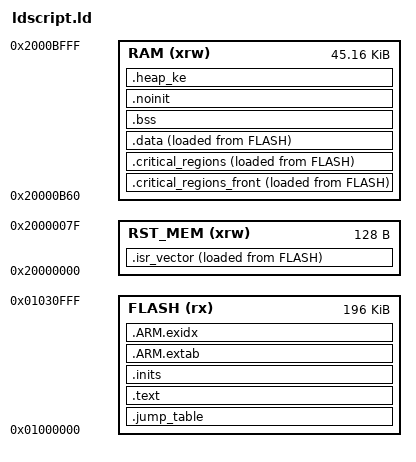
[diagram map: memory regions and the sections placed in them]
/*
 * Memory Spaces Definitions.
 *
 * Need modifying for a specific board. 
 *   FLASH.ORIGIN: starting address of flash
 *   FLASH.LENGTH: length of flash
 *   RAM.ORIGIN: starting address of RAM bank 0
 *   RAM.LENGTH: length of RAM bank 0
 *
 * The values below can be addressed in further linker scripts
 * using functions like 'ORIGIN(RAM)' or 'LENGTH(RAM)'.
 */

MEMORY
{
  FLASH (rx)    : ORIGIN = 0x01000000, LENGTH = 196K
  RST_MEM (xrw) : ORIGIN = 0x20000000, LENGTH = 0x80
  RAM (xrw)     : ORIGIN = 0x20000B60, LENGTH = 0xB4A0
}

/* 
 * The entry point is informative, for debuggers and simulators,
 * since the Cortex-M vector points to it anyway.
 */
ENTRY(app_main)


/* Sections Definitions */

SECTIONS
{
    .jump_table : ALIGN(4)
    {
        KEEP(*(jump_table_0))
        KEEP(*(jump_table_1))
        KEEP(*(jump_table_2))
        KEEP(*(jump_table_3))
        KEEP(*(jump_table_4))
        *(jump_table_0)
        *(jump_table_1)
        *(jump_table_2)
        *(jump_table_3)
        *(jump_table_4)
    } >FLASH
    
    /*
     * The program code is stored in the .text section, 
     * which goes to FLASH.
     */
    .text : ALIGN(4)
    {
        *(.text .text.*)            /* all remaining code */
 
        /* read-only data (constants) */
        *(.rodata .rodata.* .constdata .constdata.*)        

        KEEP(*(.eh_frame*))

        /*
         * Stub sections generated by the linker, to glue together 
         * ARM and Thumb code. .glue_7 is used for ARM code calling 
         * Thumb code, and .glue_7t is used for Thumb code calling 
         * ARM code. Apparently always generated by the linker, for some
         * architectures, so better leave them here.
         */
        *(.glue_7)
        *(.glue_7t)

    } >FLASH

    .inits : ALIGN(4)
    {
        /* 
         * Memory regions initialisation arrays.
         *
         * Thee are two kinds of arrays for each RAM region, one for 
         * data and one for bss. Each is iterrated at startup and the   
         * region initialisation is performed.
         * 
         * The data array includes:
         * - from (LOADADDR())
         * - region_begin (ADDR())
         * - region_end (ADDR()+SIZEOF())
         *
         * The bss array includes:
         * - region_begin (ADDR())
         * - region_end (ADDR()+SIZEOF())
         *
         * WARNING: It is mandatory that the regions are word aligned, 
         * since the initialisation code works only on words.
         */
         
        __vector_regions_array_start = .;
        LONG(LOADADDR(.isr_vector));
        LONG(ADDR(.isr_vector));
        LONG(ADDR(.isr_vector)+SIZEOF(.isr_vector));
        __vector_regions_array_end = .;
        
        __critical_regions_array_front_start = .;
        LONG(LOADADDR(.critical_regions_front));
        LONG(ADDR(.critical_regions_front));
        LONG(ADDR(.critical_regions_front)+SIZEOF(.critical_regions_front));
        __critical_regions_array_front_end = .;
        
        __critical_regions_array_start = .;
        LONG(LOADADDR(.critical_regions));
        LONG(ADDR(.critical_regions));
        LONG(ADDR(.critical_regions)+SIZEOF(.critical_regions));
        __critical_regions_array_end = .;
         
        __data_regions_array_start = .;
        LONG(LOADADDR(.data));
        LONG(ADDR(.data));
        LONG(ADDR(.data)+SIZEOF(.data));
        __data_regions_array_end = .;
        
        __bss_regions_array_start = .;
        LONG(ADDR(.bss));
        LONG(ADDR(.bss)+SIZEOF(.bss));
        __bss_regions_array_end = .;

        /* End of memory regions initialisation arrays. */
    
        /*
         * These are the old initialisation sections, intended to contain
         * naked code, with the prologue/epilogue added by crti.o/crtn.o
         * when linking with startup files. The standalone startup code
         * currently does not run these, better use the init arrays below.
         */
		KEEP(*(.init))
		KEEP(*(.fini))

		. = ALIGN(4);

		/*
         * The preinit code, i.e. an array of pointers to initialisation 
         * functions to be performed before constructors.
         */
		PROVIDE_HIDDEN (__preinit_array_start = .);
        
        /*
         * Used to run the SystemInit() before anything else.
         */
		KEEP(*(.preinit_array_sysinit .preinit_array_sysinit.*))
        
        /* 
         * Used for other platform inits.
         */
		KEEP(*(.preinit_array_platform .preinit_array_platform.*))
        
        /*
         * The application inits. If you need to enforce some order in 
         * execution, create new sections, as before.
         */
		KEEP(*(.preinit_array .preinit_array.*))

		PROVIDE_HIDDEN (__preinit_array_end = .);

		. = ALIGN(4);

		/*
         * The init code, i.e. an array of pointers to static constructors.
         */
		PROVIDE_HIDDEN (__init_array_start = .);
		KEEP(*(SORT(.init_array.*)))
		KEEP(*(.init_array))
		PROVIDE_HIDDEN (__init_array_end = .);

		. = ALIGN(4);

		/*
         * The fini code, i.e. an array of pointers to static destructors.
         */
		PROVIDE_HIDDEN (__fini_array_start = .);
		KEEP(*(SORT(.fini_array.*)))
		KEEP(*(.fini_array))
		PROVIDE_HIDDEN (__fini_array_end = .);

    } >FLASH 

	/* ARM magic sections */
	.ARM.extab : ALIGN(4)
   	{
       *(.ARM.extab* .gnu.linkonce.armextab.*)
   	} > FLASH
   	
    . = ALIGN(4);
   	__exidx_start = .;   	
   	.ARM.exidx : ALIGN(4)
   	{
       *(.ARM.exidx* .gnu.linkonce.armexidx.*)
   	} > FLASH
   	__exidx_end = .;
   	
    . = ALIGN(4);
    _etext = .;
    __etext = .;
    
    /* MEMORY_ARRAY */

	/*
     * For Cortex-M devices, the beginning of the startup code is stored in
     * the .isr_vector section, which goes to FLASH. 
     */
    .isr_vector : ALIGN(4)
    {
        FILL(0xFF)
        
        __vectors_start = ABSOLUTE(.) ;
        KEEP(*(.isr_vector))        /* Interrupt vectors */
        __vectors_end = ABSOLUTE(.) ;

    } >RST_MEM  AT>FLASH

    /*
     * The initialised data section.
     *
     * The program executes knowing that the data is in the RAM
     * but the loader puts the initial values in the FLASH (inidata).
     * It is one task of the startup to copy the initial values from 
     * FLASH to RAM.
     */
    .critical_regions_front : ALIGN(4)
    {
        *(.ram_code_front.*)            /* RAM code */
        *(ram_code_front*)            /* RAM code */
        
    } >RAM  AT>FLASH
	
    .critical_regions : ALIGN(4)
    {
        *(.ram_code.*)            /* RAM code */
        *(ram_code*)            /* RAM code */
        *(.after_vectors .after_vectors.*)  /* Startup code and ISR */
        
    } >RAM  AT>FLASH
    
    .data : ALIGN(4)
    {
    	FILL(0xFF)
        /* This is used by the startup code to initialise the .data section */
        __data_start__ = . ;
		*(.data_begin .data_begin.*)

		*(.data .data.*)
		
		*(.data_end .data_end.*)
	    . = ALIGN(4);

	    /* This is used by the startup code to initialise the .data section */
        __data_end__ = . ;

    } >RAM AT>FLASH
    
    /*
     * The uninitialised data sections. NOLOAD is used to avoid
     * the "section `.bss' type changed to PROGBITS" warning
     */

    /* The primary uninitialised data section. */
    .bss (NOLOAD) : ALIGN(4)
    {
        __bss_start__ = .;     	/* standard newlib definition */
        *(.bss_begin .bss_begin.*)

        *(.bss .bss.*)
        *(COMMON)
        
        *(.bss_end .bss_end.*)
	    . = ALIGN(4);
        __bss_end__ = .;        /* standard newlib definition */
    } >RAM
    
    .noinit (NOLOAD) : ALIGN(4)
    {
        _noinit = .;
        
        *(.noinit .noinit.*) 
        
         . = ALIGN(4) ;
        _end_noinit = .;   
    } > RAM
    
    /* Mandatory to be word aligned, _sbrk assumes this */
    PROVIDE ( end = _end_noinit ); /* was _ebss */
    PROVIDE ( _end = _end_noinit );
    PROVIDE ( __end = _end_noinit );
    PROVIDE ( __end__ = _end_noinit );
    
    .heap_ke (NOLOAD) : ALIGN(4)
    {
        KEEP(*(heap_ke))
        *(heap_ke)
    } > RAM

    /* After that there are only debugging sections. */
    
    /* This can remove the debugging information from the standard libraries */    
    /* 
    DISCARD :
    {
     libc.a ( * )
     libm.a ( * )
     libgcc.a ( * )
     }
     */
  
    /* Stabs debugging sections.  */
    .stab          0 : { *(.stab) }
    .stabstr       0 : { *(.stabstr) }
    .stab.excl     0 : { *(.stab.excl) }
    .stab.exclstr  0 : { *(.stab.exclstr) }
    .stab.index    0 : { *(.stab.index) }
    .stab.indexstr 0 : { *(.stab.indexstr) }
    .comment       0 : { *(.comment) }
    /*
     * DWARF debug sections.
     * Symbols in the DWARF debugging sections are relative to the beginning
     * of the section so we begin them at 0.  
     */
    /* DWARF 1 */
    .debug          0 : { *(.debug) }
    .line           0 : { *(.line) }
    /* GNU DWARF 1 extensions */
    .debug_srcinfo  0 : { *(.debug_srcinfo) }
    .debug_sfnames  0 : { *(.debug_sfnames) }
    /* DWARF 1.1 and DWARF 2 */
    .debug_aranges  0 : { *(.debug_aranges) }
    .debug_pubnames 0 : { *(.debug_pubnames) }
    /* DWARF 2 */
    .debug_info     0 : { *(.debug_info .gnu.linkonce.wi.*) }
    .debug_abbrev   0 : { *(.debug_abbrev) }
    .debug_line     0 : { *(.debug_line) }
    .debug_frame    0 : { *(.debug_frame) }
    .debug_str      0 : { *(.debug_str) }
    .debug_loc      0 : { *(.debug_loc) }
    .debug_macinfo  0 : { *(.debug_macinfo) }
    /* SGI/MIPS DWARF 2 extensions */
    .debug_weaknames 0 : { *(.debug_weaknames) }
    .debug_funcnames 0 : { *(.debug_funcnames) }
    .debug_typenames 0 : { *(.debug_typenames) }
    .debug_varnames  0 : { *(.debug_varnames) }    
}
